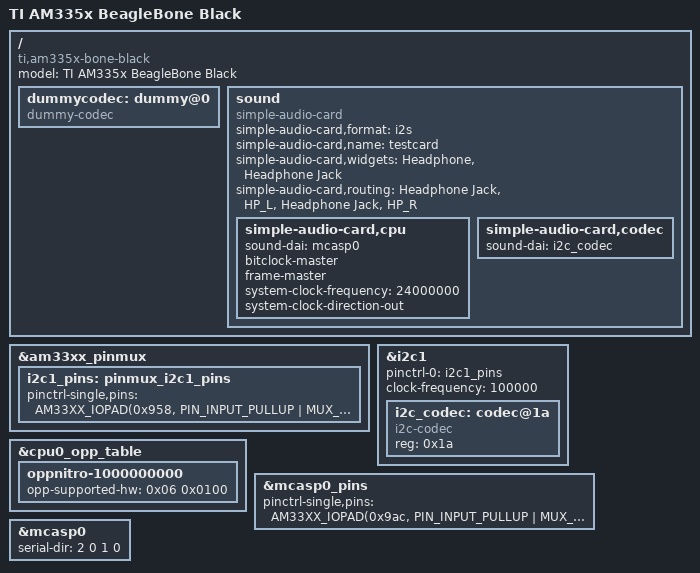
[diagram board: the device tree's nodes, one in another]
/*
 * Copyright (C) 2012 Texas Instruments Incorporated - http://www.ti.com/
 *
 * This program is free software; you can redistribute it and/or modify
 * it under the terms of the GNU General Public License version 2 as
 * published by the Free Software Foundation.
 */
/dts-v1/;

#include "am33xx.dtsi"
#include "am335x-bone-common.dtsi"
#include "am335x-boneblack-common.dtsi"

/ {
	model = "TI AM335x BeagleBone Black";
	compatible = "ti,am335x-bone-black", "ti,am335x-bone", "ti,am33xx";

	dummycodec: dummy@0 {
		#sound-dai-cells = <0>;
		compatible = "dummy-codec";
		status = "okay";
	};

	sound {
		compatible = "simple-audio-card";
	    	simple-audio-card,format = "i2s";
	    	simple-audio-card,name = "testcard";
		simple-audio-card,widgets =
                        "Headphone", "Headphone Jack";
                simple-audio-card,routing =
                        "Headphone Jack", "HP_L",
                        "Headphone Jack", "HP_R";

	    	simple-audio-card,cpu {
		    sound-dai = <&mcasp0>;
		    bitclock-master;
		    frame-master;
		    system-clock-frequency = <24000000>;
		    system-clock-direction-out;
	    	};
		simple-audio-card,codec {
			sound-dai = <&i2c_codec>;      
		};
	};
};

&am33xx_pinmux {

	i2c1_pins: pinmux_i2c1_pins {
		pinctrl-single,pins = <
			AM33XX_IOPAD(0x958, PIN_INPUT_PULLUP | MUX_MODE2)	/* spi0_d1.i2c1_sda */
			AM33XX_IOPAD(0x95c, PIN_INPUT_PULLUP | MUX_MODE2)	/* spi0_cs0.i2c1_scl */
		>;
	};
};

&i2c1 {
	pinctrl-names = "default";
	pinctrl-0 = <&i2c1_pins>;

	status = "okay";
	clock-frequency = <100000>;

       i2c_codec: codec@1a {
                compatible = "i2c-codec";
                reg = <0x1a>;
                #sound-dai-cells = <0>;
        };

/*
	i2c_codec: codec@1a {
                compatible = "i2c-codec";
		#sound-dai-cells = <0>;
                reg = <0x1a>;
        };
*/
};

&cpu0_opp_table {
	/*
	 * All PG 2.0 silicon may not support 1GHz but some of the early
	 * BeagleBone Blacks have PG 2.0 silicon which is guaranteed
	 * to support 1GHz OPP so enable it for PG 2.0 on this board.
	 */
	oppnitro-1000000000 {
		opp-supported-hw = <0x06 0x0100>;
	};
};

&mcasp0_pins {
	pinctrl-single,pins = <
			AM33XX_IOPAD(0x9ac, PIN_INPUT_PULLUP | MUX_MODE0) /* mcasp0_ahcklx.mcasp0_ahclkx */
			AM33XX_IOPAD(0x99c, PIN_OUTPUT_PULLDOWN | MUX_MODE2) /* mcasp0_ahclkr.mcasp0_axr2*/
			AM33XX_IOPAD(0x998, PIN_INPUT_PULLUP | MUX_MODE0) /* Added for RX */
			AM33XX_IOPAD(0x994, PIN_OUTPUT_PULLUP | MUX_MODE0) /* mcasp0_fsx.mcasp0_fsx */
			AM33XX_IOPAD(0x990, PIN_OUTPUT_PULLDOWN | MUX_MODE0) /* mcasp0_aclkx.mcasp0_aclkx */
			AM33XX_IOPAD(0x86c, PIN_OUTPUT_PULLDOWN | MUX_MODE7) /* gpmc_a11.GPIO1_27 */
		>;
};

&mcasp0 {
	serial-dir = <2 0 1 0>;
};
